# RZT2ME register map
Vendor: Renesas Electronics Corporation; Series: RZT; File version: 1.00.00
CPU: other r0p0, little endian, MPU, no FPU, VTOR, 4 interrupt priority bits, 624 interrupts
Registers are 32-bit, read-write, reset 0x0 unless marked. A register's access mark holds for its fields unless they carry their own. Offsets are from the block's base; [hi:lo] are bit positions; 'fields as' and 'values as' point back to an identical list.

## POE3 — Port Output Enable 3
Base 0x90005000
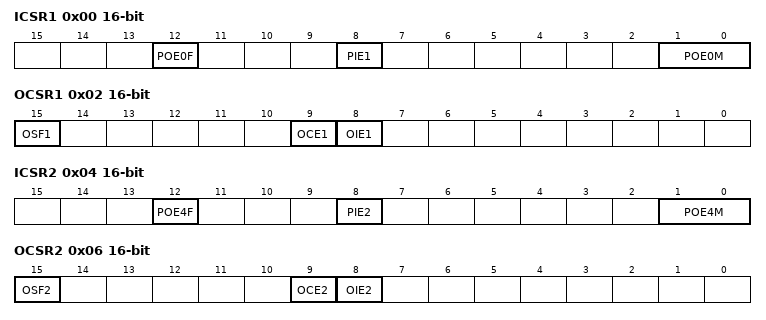
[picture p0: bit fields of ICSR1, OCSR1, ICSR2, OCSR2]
0x00 ICSR1 16-bit — Input Level Control/Status Register 1
  [12] POE0F — POE0 Flag
    0=Indicates that a high-impedance request has not been input to the POE0# pin; 1=Indicates that a high-impedance request has been input to the POE0# pin
  [8] PIE1 — Port Interrupt Enable 1
    0=Interrupt requests disabled; 1=Interrupt requests enabled
  [1:0] POE0M — POE0 Mode Select
    0=Accepts a request on the falling edge of POE0# pin input; 1=Accepts a request when POE0# pin input has been sampled 16 times at PCLKH/8 clock pulses and all are low level; 2=Accepts a request when POE0# pin input has been sampled 16 times at PCLKH/16 clock pulses and all are low level; 3=Accepts a request when POE0# pin input has been sampled 16 times at PCLKH/128 clock pulses and all are low level
0x02 OCSR1 16-bit — Output Level Control/Status Register 1
  [15] OSF1 — Output Short Circuit Flag 1
    0=Indicates that outputs have not simultaneously become an active level; 1=Indicates that outputs have simultaneously become an active level
  [9] OCE1 — Output Short Circuit High-Impedance Enable 1
    0=Does not place the pins in the high-impedance state; 1=Places the pins in the high-impedance state
  [8] OIE1 — Output Short Circuit Interrupt Enable 1
    0=Interrupt requests disabled; 1=Interrupt requests enabled
0x04 ICSR2 16-bit — Input Level Control/Status Register 2
  [12] POE4F — POE4 Flag
    0=Indicates that a high-impedance request has not been input to the POE4# pin; 1=Indicates that a high-impedance request has been input to the POE4# pin
  [8] PIE2 — Port Interrupt Enable 2
    0=Interrupt requests disabled; 1=Interrupt requests enabled
  [1:0] POE4M — POE4 Mode Select
    0=Accepts a request on the falling edge of POE4# pin input; 1=Accepts a request when POE4# pin input has been sampled 16 times at PCLKH/8 clock pulses and all are low level; 2=Accepts a request when POE4# pin input has been sampled 16 times at PCLKH/16 clock pulses and all are low level; 3=Accepts a request when POE4# pin input has been sampled 16 times at PCLKH/128 clock pulses and all are low level
0x06 OCSR2 16-bit — Output Level Control/Status Register 2
  [15] OSF2 — Output Short Circuit Flag 2
    values as OCSR1.OSF1
  [9] OCE2 — Output Short Circuit High-Impedance Enable 2
    values as OCSR1.OCE1
  [8] OIE2 — Output Short Circuit Interrupt Enable 2
    0=Interrupt requests disabled; 1=Interrupt requests enabled
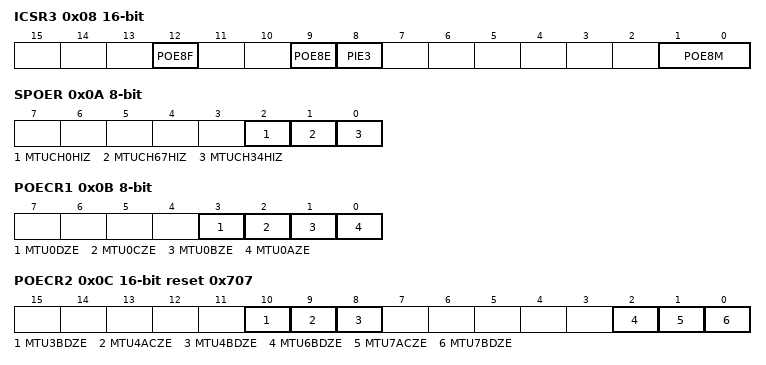
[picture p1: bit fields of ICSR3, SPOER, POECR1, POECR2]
0x08 ICSR3 16-bit — Input Level Control/Status Register 3
  [12] POE8F — POE8 Flag
    0=Indicates that a high-impedance request has not been input to the POE8# pin; 1=Indicates that a high-impedance request has been input to the POE8# pin
  [9] POE8E — POE8 High-Impedance Enable
    0=Does not place the pin in the high-impedance state; 1=Places the pin in the high-impedance state
  [8] PIE3 — Port Interrupt Enable 3
    0=Interrupt requests disabled; 1=Interrupt requests enabled
  [1:0] POE8M — POE8 Mode Select
    0=Accepts a request on the falling edge of POE8# pin input; 1=Accepts a request when POE8# pin input has been sampled 16 times at PCLKH/8 clock pulses and all are low level; 2=Accepts a request when POE8# pin input has been sampled 16 times at PCLKH/16 clock pulses and all are low level; 3=Accepts a request when POE8# pin input has been sampled 16 times at PCLKH/128 clock pulses and all are low level
0x0A SPOER 8-bit — Software Port Output Enable Register
  [all] fields
    values as OCSR1.OCE1
  [2] MTUCH0HIZ — MTU0 Pin High-Impedance Enable
  [1] MTUCH67HIZ — MTU6 and MTU7 Output High-Impedance Enable
  [0] MTUCH34HIZ — MTU3 and MTU4 Output High-Impedance Enable
0x0B POECR1 8-bit — Port Output Enable Control Register 1
  [all] fields
    0=Does not place the pin in high-impedance state; 1=Places the pin in high-impedance state
  [3] MTU0DZE — MTIOC0D High-Impedance Enable
  [2] MTU0CZE — MTIOC0C High-Impedance Enable
  [1] MTU0BZE — MTIOC0B High-Impedance Enable
  [0] MTU0AZE — MTIOC0A High-Impedance Enable
0x0C POECR2 16-bit reset 0x707 — Port Output Enable Control Register 2
  [all] fields
    0=Does not place the pins in high-impedance state; 1=Places the pins in high-impedance state
  [10] MTU3BDZE — MTIOC3B/MTIOC3D High-Impedance Enable
  [9] MTU4ACZE — MTIOC4A/MTIOC4C High-Impedance Enable
  [8] MTU4BDZE — MTIOC4B/MTIOC4D High-Impedance Enable
  [2] MTU6BDZE — MTIOC6B/MTIOC6D High-Impedance Enable
  [1] MTU7ACZE — MTIOC7A/MTIOC7C High-Impedance Enable
  [0] MTU7BDZE — MTIOC7B/MTIOC7D High-Impedance Enable
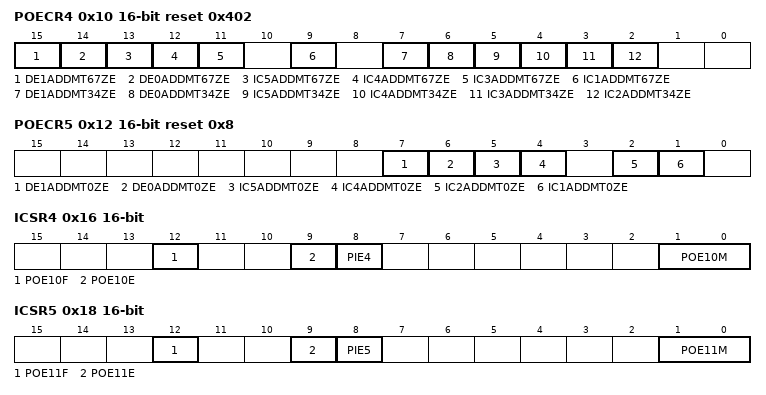
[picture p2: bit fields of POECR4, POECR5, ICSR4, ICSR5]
0x10 POECR4 16-bit reset 0x402 — Port Output Enable Control Register 4
  [15] DE1ADDMT67ZE — MTU6 and MTU7 High-Impedance DERR1ST Add
    0=Does not add the status to the high-impedance control conditions; 1=Adds the status to the high-impedance control conditions
  [14] DE0ADDMT67ZE — MTU6 and MTU7 High-Impedance DERR0ST Add
    values as DE1ADDMT67ZE
  [13] IC5ADDMT67ZE — MTU6 and MTU7 High-Impedance POE11F Add
    0=Does not add the flag to the high-impedance control conditions; 1=Adds the flag to the high-impedance control conditions
  [12] IC4ADDMT67ZE — MTU6 and MTU7 High-Impedance POE10F Add
    values as IC5ADDMT67ZE
  [11] IC3ADDMT67ZE — MTU6 and MTU7 High-Impedance POE8F Add
    values as IC5ADDMT67ZE
  [9] IC1ADDMT67ZE — MTU6 and MTU7 High-Impedance POE0F Add
    values as IC5ADDMT67ZE
  [7] DE1ADDMT34ZE — MTU3 and MTU4 High-Impedance DERR1ST Add
    values as DE1ADDMT67ZE
  [6] DE0ADDMT34ZE — MTU3 and MTU4 High-Impedance DERR0ST Add
    values as DE1ADDMT67ZE
  [5] IC5ADDMT34ZE — MTU3 and MTU4 High-Impedance POE11F Add
    values as IC5ADDMT67ZE
  [4] IC4ADDMT34ZE — MTU3 and MTU4 High-Impedance POE10F Add
    values as IC5ADDMT67ZE
  [3] IC3ADDMT34ZE — MTU3 and MTU4 High-Impedance POE8F Add
    values as IC5ADDMT67ZE
  [2] IC2ADDMT34ZE — MTU3 and MTU4 High-Impedance POE4F Add
    values as IC5ADDMT67ZE
0x12 POECR5 16-bit reset 0x8 — Port Output Enable Control Register 5
  [7] DE1ADDMT0ZE — MTU0 High-Impedance DERR1ST Add
    values as POECR4.DE1ADDMT67ZE
  [6] DE0ADDMT0ZE — MTU0 High-Impedance DERR0ST Add
    values as POECR4.DE1ADDMT67ZE
  [5] IC5ADDMT0ZE — MTU0 High-Impedance POE11F Add
    values as POECR4.IC5ADDMT67ZE
  [4] IC4ADDMT0ZE — MTU0 High-Impedance POE10F Add
    values as POECR4.IC5ADDMT67ZE
  [2] IC2ADDMT0ZE — MTU0 High-Impedance POE4F Add
    values as POECR4.IC5ADDMT67ZE
  [1] IC1ADDMT0ZE — MTU0 High-Impedance POE0F Add
    values as POECR4.IC5ADDMT67ZE
0x16 ICSR4 16-bit — Input Level Control/Status Register 4
  [12] POE10F — POE10 Flag
    0=Indicates that a high-impedance request has not been input to the POE10# pin; 1=Indicates that a high-impedance request has been input to the POE10# pin
  [9] POE10E — POE10 High-Impedance Enable
    values as ICSR3.POE8E
  [8] PIE4 — Port Interrupt Enable 4
    0=Interrupt requests disabled; 1=Interrupt requests enabled
  [1:0] POE10M — POE10 Mode Select
    0=Accepts a request on the falling edge of POE10# pin input; 1=Accepts a request when POE10# pin input has been sampled 16 times at PCLKH/8 clock pulses and all are low level; 2=Accepts a request when POE10# pin input has been sampled 16 times at PCLKH/16 clock pulses and all are low level; 3=Accepts a request when POE10# pin input has been sampled 16 times at PCLKH/128 clock pulses and all are low level
0x18 ICSR5 16-bit — Input Level Control/Status Register 5
  [12] POE11F — POE11 Flag
    0=Indicates that a high-impedance request has not been input to the POE11# pin; 1=Indicates that a high-impedance request has been input to the POE11# pin
  [9] POE11E — POE11 High-Impedance Enable
    values as ICSR3.POE8E
  [8] PIE5 — Port Interrupt Enable 5
    0=Interrupt requests disabled; 1=Interrupt requests enabled
  [1:0] POE11M — POE11 Mode Select
    0=Accepts a request on the falling edge of POE11# pin input; 1=Accepts a request when POE11# pin input has been sampled 16 times at PCLKH/8 clock pulses and all are low level; 2=Accepts a request when POE11# pin input has been sampled 16 times at PCLKH/16 clock pulses and all are low level; 3=Accepts a request when POE11# pin input has been sampled 16 times at PCLKH/128 clock pulses and all are low level
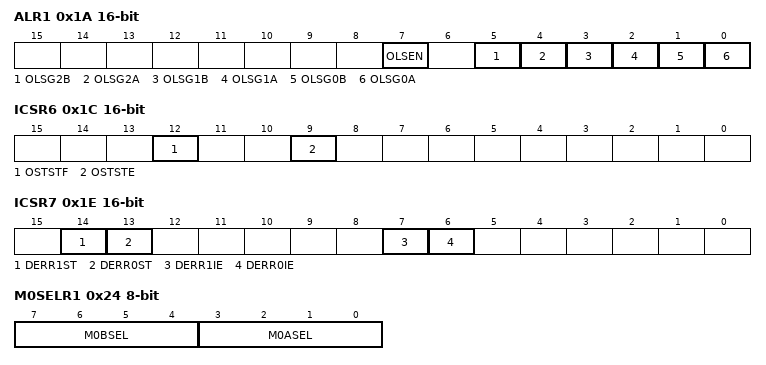
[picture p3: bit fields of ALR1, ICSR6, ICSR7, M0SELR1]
0x1A ALR1 16-bit — Active Level Setting Register 1
  [7] OLSEN — Active Level Setting Enable
    0=Disabled; 1=Enabled
  [5] OLSG2B — MTIOC4D Pin Active Level Setting
    0=Active low; 1=Active high
  [4] OLSG2A — MTIOC4B Pin Active Level Setting
    0=Active-low; 1=Active-high
  [3] OLSG1B — MTIOC4C Pin Active Level Setting
    0=Active-low; 1=Active-high
  [2] OLSG1A — MTIOC4A Pin Active Level Setting
    0=Active-low; 1=Active-high
  [1] OLSG0B — MTIOC3D Pin Active Level Setting
    0=Active-low; 1=Active-high
  [0] OLSG0A — MTIOC3B Pin Active Level Setting
    0=Active-low; 1=Active-high
0x1C ICSR6 16-bit — Input Level Control/Status Register 6
  [12] OSTSTF — Oscillation Stop High-Impedance Flag
    0=Indicates that a high-impedance request or oscillation abnormality has not been generated; 1=Indicates that a high-impedance request by oscillation stop or oscillation abnormality has been generated
  [9] OSTSTE — Oscillation Stop High-Impedance Enable
    0=Does not place the MTU complementary PWM output pins and MTU0 pins in high-impedance state; 1=Places the MTU complementary PWM output pins and MTU0 pins in high-impedance state
0x1E ICSR7 16-bit — Input Level Control/Status Register 7
  [14] DERR1ST ro — DSMIF1 Error Status
    0=Indicates that DSMIF1 error has not been generated; 1=Indicates that DSMIF1 error has been generated
  [13] DERR0ST ro — DSMIF0 Error Status
    0=Indicates that DSMIF0 error has not been generated; 1=Indicates that DSMIF0 error has been generated
  [7] DERR1IE — DSMIF1 Error Interrupt Enable
    0=Interrupt is disabled; 1=Interrupt is enabled
  [6] DERR0IE — DSMIF0 Error Interrupt Enable
    0=Interrupt is disabled; 1=Interrupt is enabled
0x24 M0SELR1 8-bit — MTU0 Pin Select Register 1
  [7:4] M0BSEL — MTU0-B (MTIOC0B) Pin Select
    0=Controls the high-impedance state of P11_5 when it is in use as the MTIOC0B pin; 1=Controls the high-impedance state of P14_4 when it is in use as the MTIOC0B pin; 2=Controls the high-impedance state of P24_0 when it is in use as the MTIOC0B pin; 3=Controls the high-impedance state of P13_3 when it is in use as the MTIOC0B pin; other=Others (Setting prohibited.)
  [3:0] M0ASEL — MTU0-A (MTIOC0A) Pin Select
    0=Controls the high-impedance state of P13_2 when it is in use as the MTIOC0A pin; 1=Controls the high-impedance state of P14_3 when it is in use as the MTIOC0A pin; 2=Controls the high-impedance state of P23_7 when it is in use as the MTIOC0A pin; other=Others (Setting prohibited.)
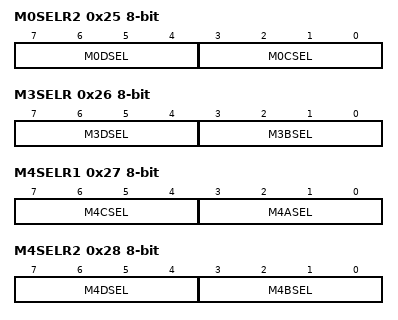
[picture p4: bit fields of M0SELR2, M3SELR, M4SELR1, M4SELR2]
0x25 M0SELR2 8-bit — MTU0 Pin Select Register 2
  [7:4] M0DSEL — MTU0-D (MTIOC0D) Pin Select
    0=Controls the high-impedance state of P13_4 when it is in use as the MTIOC0D pin; 1=Controls the high-impedance state of P15_2 when it is in use as the MTIOC0D pin; 2=Controls the high-impedance state of P24_2 when it is in use as the MTIOC0D pin; other=Others (Setting prohibited.)
  [3:0] M0CSEL — MTU0-C (MTIOC0C) Pin Select
    0=Controls the high-impedance state of P13_3 when it is in use as the MTIOC0C pin; 1=Controls the high-impedance state of P15_1 when it is in use as the MTIOC0C pin; 2=Controls the high-impedance state of P24_1 when it is in use as the MTIOC0C pin; other=Others (Setting prohibited.)
0x26 M3SELR 8-bit — MTU3 Pin Select Register
  [7:4] M3DSEL — MTU3-D (MTIOC3D) Pin Select
    0=Controls the high-impedance state of P18_1 when it is in use as the MTIOC3D pin; 1=Controls the high-impedance state of P01_1 when it is in use as the MTIOC3D pin; 2=Controls the high-impedance state of P04_0 when it is in use as the MTIOC3D pin; other=Others (Setting prohibited.)
  [3:0] M3BSEL — MTU3-B (MTIOC3B) Pin Select
    0=Controls the high-impedance state of P17_6 when it is in use as the MTIOC3B pin; 1=Controls the high-impedance state of P00_6 when it is in use as the MTIOC3B pin; 2=Controls the high-impedance state of P03_6 when it is in use as the MTIOC3B pin; other=Others (Setting prohibited.)
0x27 M4SELR1 8-bit — MTU4 Pin Select Register 1
  [7:4] M4CSEL — MTU4-C (MTIOC4C) Pin Select
    0=Controls the high-impedance state of P18_0 when it is in use as the MTIOC4C pin; 1=Controls the high-impedance state of P01_0 when it is in use as the MTIOC4C pin; 2=Controls the high-impedance state of P05_2 when it is in use as the MTIOC4C pin; 3=Controls the high-impedance state of P17_7 when it is in use as the MTIOC4C pin; other=Others (Setting prohibited.)
  [3:0] M4ASEL — MTU4-A (MTIOC4A) Pin Select
    0=Controls the high-impedance state of P17_7 when it is in use as the MTIOC4A pin; 1=Controls the high-impedance state of P00_7 when it is in use as the MTIOC4A pin; 2=Controls the high-impedance state of P05_0 when it is in use as the MTIOC4A pin; 3=Controls the high-impedance state of P18_0 when it is in use as the MTIOC4A pin; other=Others (Setting prohibited.)
0x28 M4SELR2 8-bit — MTU4 Pin Select Register 2
  [7:4] M4DSEL — MTU4-D (MTIOC4D) Pin Select
    0=Controls the high-impedance state of P18_3 when it is in use as the MTIOC4D pin; 1=Controls the high-impedance state of P01_3 when it is in use as the MTIOC4D pin; 2=Controls the high-impedance state of P05_3 when it is in use as the MTIOC4D pin; 3=Controls the high-impedance state of P18_2 when it is in use as the MTIOC4D pin; other=Others (Setting prohibited.)
  [3:0] M4BSEL — MTU4-B (MTIOC4B) Pin Select
    0=Controls the high-impedance state of P18_2 when it is in use as the MTIOC4B pin; 1=Controls the high-impedance state of P01_2 when it is in use as the MTIOC4B pin; 2=Controls the high-impedance state of P05_1 when it is in use as the MTIOC4B pin; 3=Controls the high-impedance state of P18_3 when it is in use as the MTIOC4B pin; other=Others (Setting prohibited.)
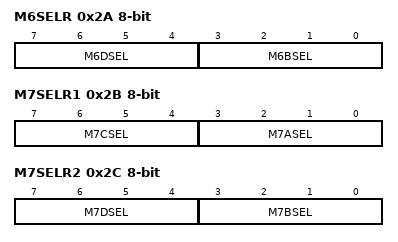
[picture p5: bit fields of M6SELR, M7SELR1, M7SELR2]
0x2A M6SELR 8-bit — MTU6 Pin Select Register
  [7:4] M6DSEL — MTU6-D (MTIOC6D) Pin Select
    0=Controls the high-impedance state of P19_6 when it is in use as the MTIOC6D pin; 1=Controls the high-impedance state of P21_4 when it is in use as the MTIOC6D pin; 2=Controls the high-impedance state of P08_7 when it is in use as the MTIOC6D pin; other=Others (Setting prohibited.)
  [3:0] M6BSEL — MTU6-B (MTIOC6B) Pin Select
    0=Controls the high-impedance state of P19_3 when it is in use as the MTIOC6B pin; 1=Controls the high-impedance state of P21_2 when it is in use as the MTIOC6B pin; 2=Controls the high-impedance state of P08_5 when it is in use as the MTIOC6B pin; other=Others (Setting prohibited.)
0x2B M7SELR1 8-bit — MTU7 Pin Select Register 1
  [7:4] M7CSEL — MTU7-C (MTIOC7C) Pin Select
    0=Controls the high-impedance state of P19_5 when it is in use as the MTIOC7C pin; 1=Controls the high-impedance state of P21_7 when it is in use as the MTIOC7C pin; 2=Controls the high-impedance state of P09_2 when it is in use as the MTIOC7C pin; other=Others (Setting prohibited.)
  [3:0] M7ASEL — MTU7-A (MTIOC7A) Pin Select
    0=Controls the high-impedance state of P19_4 when it is in use as the MTIOC7A pin; 1=Controls the high-impedance state of P21_5 when it is in use as the MTIOC7A pin; 2=Controls the high-impedance state of P09_0 when it is in use as the MTIOC7A pin; other=Others (Setting prohibited.)
0x2C M7SELR2 8-bit — MTU7 Pin Select Register 2
  [7:4] M7DSEL — MTU7-D (MTIOC7D) Pin Select
    0=Controls the high-impedance state of P20_0 when it is in use as the MTIOC7D pin; 1=Controls the high-impedance state of P22_0 when it is in use as the MTIOC7D pin; 2=Controls the high-impedance state of P09_3 when it is in use as the MTIOC7D pin; other=Others (Setting prohibited.)
  [3:0] M7BSEL — MTU7-B (MTIOC7B) Pin Select
    0=Controls the high-impedance state of P19_7 when it is in use as the MTIOC7B pin; 1=Controls the high-impedance state of P21_6 when it is in use as the MTIOC7B pin; 2=Controls the high-impedance state of P09_1 when it is in use as the MTIOC7B pin; other=Others (Setting prohibited.)
